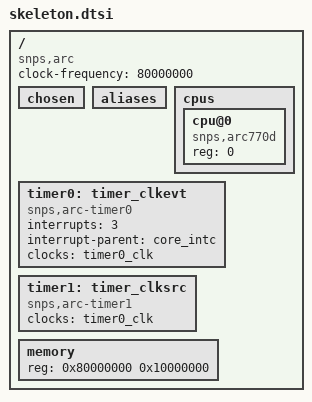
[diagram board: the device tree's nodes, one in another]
/*
 * Copyright (C) 2012 Synopsys, Inc. (www.synopsys.com)
 *
 * This program is free software; you can redistribute it and/or modify
 * it under the terms of the GNU General Public License version 2 as
 * published by the Free Software Foundation.
 */

/*
 * Skeleton device tree; the bare minimum needed to boot; just include and
 * add a compatible value.
 */

/ {
	compatible = "snps,arc";
	clock-frequency = <80000000>;	/* 80 MHZ */
	#address-cells = <1>;
	#size-cells = <1>;
	chosen { };
	aliases { };

	cpus {
		#address-cells = <1>;
		#size-cells = <0>;

		cpu@0 {
			device_type = "cpu";
			compatible = "snps,arc770d";
			reg = <0>;
		};
	};

	timer0: timer_clkevt {
		compatible = "snps,arc-timer0";
		interrupts = <3>;
		interrupt-parent = <&core_intc>;
		clocks = <&timer0_clk>;
	};

	timer1: timer_clksrc {
		compatible = "snps,arc-timer1";
		clocks = <&timer0_clk>;
	};

	memory {
		device_type = "memory";
		reg = <0x80000000 0x10000000>;	/* 256M */
	};
};
